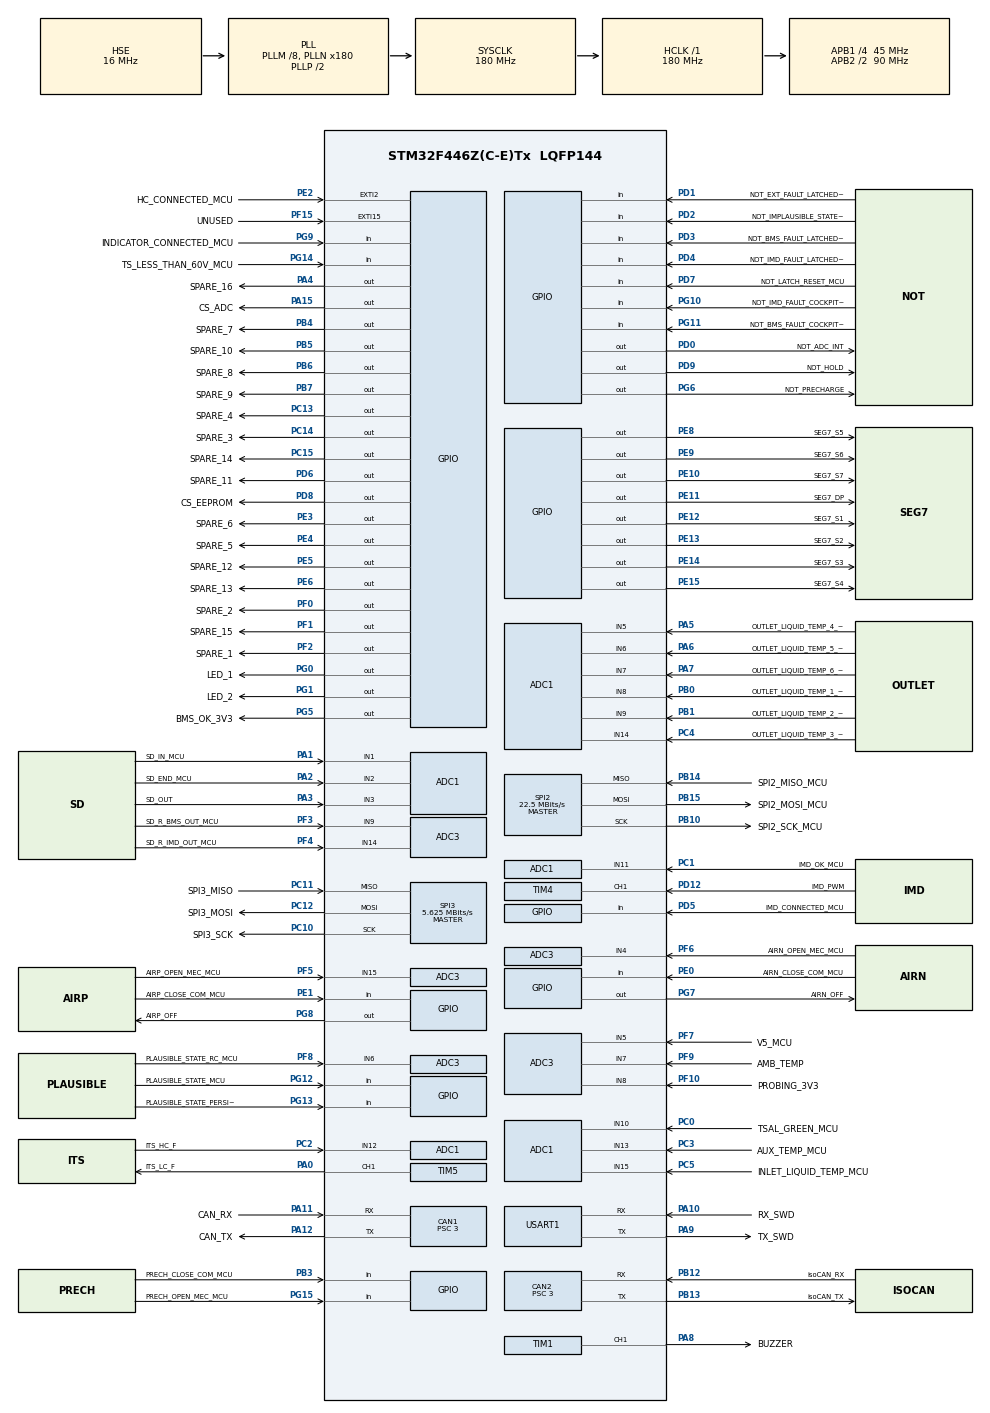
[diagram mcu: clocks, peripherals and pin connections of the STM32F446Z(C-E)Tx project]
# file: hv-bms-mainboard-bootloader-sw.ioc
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ADC1.Channel-0\#ChannelRegularConversion=ADC_CHANNEL_15
ADC1.Channel-1\#ChannelRegularConversion=ADC_CHANNEL_1
ADC1.Channel-10\#ChannelRegularConversion=ADC_CHANNEL_11
ADC1.Channel-11\#ChannelRegularConversion=ADC_CHANNEL_12
ADC1.Channel-12\#ChannelRegularConversion=ADC_CHANNEL_13
ADC1.Channel-13\#ChannelRegularConversion=ADC_CHANNEL_14
ADC1.Channel-14\#ChannelRegularConversion=ADC_CHANNEL_15
ADC1.Channel-2\#ChannelRegularConversion=ADC_CHANNEL_2
ADC1.Channel-3\#ChannelRegularConversion=ADC_CHANNEL_3
ADC1.Channel-4\#ChannelRegularConversion=ADC_CHANNEL_5
ADC1.Channel-5\#ChannelRegularConversion=ADC_CHANNEL_6
ADC1.Channel-6\#ChannelRegularConversion=ADC_CHANNEL_7
ADC1.Channel-7\#ChannelRegularConversion=ADC_CHANNEL_8
ADC1.Channel-8\#ChannelRegularConversion=ADC_CHANNEL_9
ADC1.Channel-9\#ChannelRegularConversion=ADC_CHANNEL_10
ADC1.ClockPrescaler=ADC_CLOCK_SYNC_PCLK_DIV4
ADC1.DiscontinuousConvMode=DISABLE
ADC1.EOCSelection=ADC_EOC_SEQ_CONV
ADC1.NbrOfConversion=15
ADC1.NbrOfConversionFlag=1
ADC1.Rank-0\#ChannelRegularConversion=1
ADC1.Rank-1\#ChannelRegularConversion=2
ADC1.Rank-10\#ChannelRegularConversion=11
ADC1.Rank-11\#ChannelRegularConversion=12
ADC1.Rank-12\#ChannelRegularConversion=13
ADC1.Rank-13\#ChannelRegularConversion=14
ADC1.Rank-14\#ChannelRegularConversion=15
ADC1.Rank-2\#ChannelRegularConversion=3
ADC1.Rank-3\#ChannelRegularConversion=4
ADC1.Rank-4\#ChannelRegularConversion=5
ADC1.Rank-5\#ChannelRegularConversion=6
ADC1.Rank-6\#ChannelRegularConversion=7
ADC1.Rank-7\#ChannelRegularConversion=8
ADC1.Rank-8\#ChannelRegularConversion=9
ADC1.Rank-9\#ChannelRegularConversion=10
ADC1.SamplingTime-0\#ChannelRegularConversion=ADC_SAMPLETIME_15CYCLES
ADC1.SamplingTime-1\#ChannelRegularConversion=ADC_SAMPLETIME_15CYCLES
ADC1.SamplingTime-10\#ChannelRegularConversion=ADC_SAMPLETIME_15CYCLES
ADC1.SamplingTime-11\#ChannelRegularConversion=ADC_SAMPLETIME_15CYCLES
ADC1.SamplingTime-12\#ChannelRegularConversion=ADC_SAMPLETIME_15CYCLES
ADC1.SamplingTime-13\#ChannelRegularConversion=ADC_SAMPLETIME_15CYCLES
ADC1.SamplingTime-14\#ChannelRegularConversion=ADC_SAMPLETIME_15CYCLES
ADC1.SamplingTime-2\#ChannelRegularConversion=ADC_SAMPLETIME_15CYCLES
ADC1.SamplingTime-3\#ChannelRegularConversion=ADC_SAMPLETIME_15CYCLES
ADC1.SamplingTime-4\#ChannelRegularConversion=ADC_SAMPLETIME_15CYCLES
ADC1.SamplingTime-5\#ChannelRegularConversion=ADC_SAMPLETIME_15CYCLES
ADC1.SamplingTime-6\#ChannelRegularConversion=ADC_SAMPLETIME_15CYCLES
ADC1.SamplingTime-7\#ChannelRegularConversion=ADC_SAMPLETIME_15CYCLES
ADC1.SamplingTime-8\#ChannelRegularConversion=ADC_SAMPLETIME_15CYCLES
ADC1.SamplingTime-9\#ChannelRegularConversion=ADC_SAMPLETIME_15CYCLES
ADC1.master=1
ADC3.Channel-10\#ChannelRegularConversion=ADC_CHANNEL_8
ADC3.Channel-11\#ChannelRegularConversion=ADC_CHANNEL_9
ADC3.Channel-12\#ChannelRegularConversion=ADC_CHANNEL_14
ADC3.Channel-13\#ChannelRegularConversion=ADC_CHANNEL_15
ADC3.Channel-6\#ChannelRegularConversion=ADC_CHANNEL_4
ADC3.Channel-7\#ChannelRegularConversion=ADC_CHANNEL_5
ADC3.Channel-8\#ChannelRegularConversion=ADC_CHANNEL_6
ADC3.Channel-9\#ChannelRegularConversion=ADC_CHANNEL_7
ADC3.EOCSelection=ADC_EOC_SEQ_CONV
ADC3.NbrOfConversion=8
ADC3.NbrOfConversionFlag=1
ADC3.Rank-10\#ChannelRegularConversion=5
ADC3.Rank-11\#ChannelRegularConversion=6
ADC3.Rank-12\#ChannelRegularConversion=7
ADC3.Rank-13\#ChannelRegularConversion=8
ADC3.Rank-6\#ChannelRegularConversion=1
ADC3.Rank-7\#ChannelRegularConversion=2
ADC3.Rank-8\#ChannelRegularConversion=3
ADC3.Rank-9\#ChannelRegularConversion=4
ADC3.SamplingTime-10\#ChannelRegularConversion=ADC_SAMPLETIME_15CYCLES
ADC3.SamplingTime-11\#ChannelRegularConversion=ADC_SAMPLETIME_15CYCLES
ADC3.SamplingTime-12\#ChannelRegularConversion=ADC_SAMPLETIME_15CYCLES
ADC3.SamplingTime-13\#ChannelRegularConversion=ADC_SAMPLETIME_3CYCLES
ADC3.SamplingTime-6\#ChannelRegularConversion=ADC_SAMPLETIME_15CYCLES
ADC3.SamplingTime-7\#ChannelRegularConversion=ADC_SAMPLETIME_15CYCLES
ADC3.SamplingTime-8\#ChannelRegularConversion=ADC_SAMPLETIME_15CYCLES
ADC3.SamplingTime-9\#ChannelRegularConversion=ADC_SAMPLETIME_15CYCLES
ADC3.ScanConvMode=ENABLE
CAN1.BS1=CAN_BS1_12TQ
CAN1.BS2=CAN_BS2_2TQ
CAN1.CalculateBaudRate=1000000
CAN1.CalculateTimeBit=1000
CAN1.CalculateTimeQuantum=66.66666666666666
CAN1.Prescaler=3
CAN2.BS1=CAN_BS1_12TQ
CAN2.BS2=CAN_BS2_2TQ
CAN2.CalculateBaudRate=1000000
CAN2.CalculateTimeBit=1000
CAN2.CalculateTimeQuantum=66.66666666666666
CAN2.Prescaler=3
Dma.ADC1.0.Direction=DMA_PERIPH_TO_MEMORY
Dma.ADC1.0.FIFOMode=DMA_FIFOMODE_DISABLE
Dma.ADC1.0.Instance=DMA2_Stream0
Dma.ADC1.0.MemDataAlignment=DMA_MDATAALIGN_HALFWORD
Dma.ADC1.0.MemInc=DMA_MINC_ENABLE
Dma.ADC1.0.Mode=DMA_CIRCULAR
Dma.ADC1.0.PeriphDataAlignment=DMA_PDATAALIGN_HALFWORD
Dma.ADC1.0.PeriphInc=DMA_PINC_DISABLE
Dma.ADC1.0.Priority=DMA_PRIORITY_LOW
Dma.ADC3.1.Direction=DMA_PERIPH_TO_MEMORY
Dma.ADC3.1.FIFOMode=DMA_FIFOMODE_DISABLE
Dma.ADC3.1.Instance=DMA2_Stream1
Dma.ADC3.1.MemDataAlignment=DMA_MDATAALIGN_HALFWORD
Dma.ADC3.1.MemInc=DMA_MINC_ENABLE
Dma.ADC3.1.Mode=DMA_CIRCULAR
Dma.ADC3.1.PeriphDataAlignment=DMA_PDATAALIGN_HALFWORD
Dma.ADC3.1.PeriphInc=DMA_PINC_DISABLE
Dma.ADC3.1.Priority=DMA_PRIORITY_LOW
Dma.Request0=ADC1
Dma.Request1=ADC3
Mcu.Family=STM32F4
Mcu.Name=STM32F446Z(C-E)Tx
Mcu.Package=LQFP144
NVIC.CAN1_RX0_IRQn=true\:0\:0\:false\:false\:true\:true\:true\:true
NVIC.CAN1_RX1_IRQn=true\:0\:0\:false\:false\:true\:true\:true\:true
NVIC.CAN2_RX0_IRQn=true\:0\:0\:false\:false\:true\:true\:true\:true
NVIC.CAN2_RX1_IRQn=true\:0\:0\:false\:false\:true\:true\:true\:true
NVIC.DMA2_Stream0_IRQn=true\:0\:0\:false\:false\:true\:false\:true\:true
NVIC.DMA2_Stream1_IRQn=true\:0\:0\:false\:false\:true\:false\:true\:true
NVIC.EXTI2_IRQn=true\:0\:0\:false\:false\:true\:true\:true\:true
NVIC.PriorityGroup=NVIC_PRIORITYGROUP_4
NVIC.TIM4_IRQn=true\:0\:0\:false\:false\:true\:true\:true\:true
NVIC.TIM6_DAC_IRQn=true\:0\:0\:false\:false\:true\:true\:true\:true
NVIC.TIM7_IRQn=true\:0\:0\:false\:false\:true\:true\:true\:true
PA0-WKUP.GPIO_Label=ITS_LC_F
PA0-WKUP.Signal=S_TIM5_CH1
PA1.GPIO_Label=SD_IN_MCU
PA1.Signal=ADCx_IN1
PA10.GPIO_Label=RX_SWD
PA10.Mode=Asynchronous
PA10.Signal=USART1_RX
PA11.GPIO_Label=CAN_RX
PA11.Mode=CAN_Activate
PA11.Signal=CAN1_RX
PA12.GPIO_Label=CAN_TX
PA12.Mode=CAN_Activate
PA12.Signal=CAN1_TX
PA13.GPIO_Label=SWDIO
PA13.Mode=Serial_Wire
PA13.Signal=SYS_JTMS-SWDIO
PA14.GPIO_Label=SWCLK
PA14.Mode=Serial_Wire
PA14.Signal=SYS_JTCK-SWCLK
PA15.GPIO_Label=CS_ADC
PA15.Signal=GPIO_Output
PA2.GPIO_Label=SD_END_MCU
PA2.Signal=ADCx_IN2
PA3.GPIO_Label=SD_OUT
PA3.Signal=ADCx_IN3
PA4.GPIO_Label=SPARE_16
PA4.Signal=GPIO_Output
PA5.GPIO_Label=OUTLET_LIQUID_TEMP_4_MCU
PA5.Signal=ADCx_IN5
PA6.GPIO_Label=OUTLET_LIQUID_TEMP_5_MCU
PA6.Signal=ADCx_IN6
PA7.GPIO_Label=OUTLET_LIQUID_TEMP_6_MCU
PA7.Signal=ADCx_IN7
PA8.GPIO_Label=BUZZER
PA8.Signal=S_TIM1_CH1
PA9.GPIO_Label=TX_SWD
PA9.Mode=Asynchronous
PA9.Signal=USART1_TX
PB0.GPIO_Label=OUTLET_LIQUID_TEMP_1_MCU
PB0.Signal=ADCx_IN8
PB1.GPIO_Label=OUTLET_LIQUID_TEMP_2_MCU
PB1.Signal=ADCx_IN9
PB10.GPIO_Label=SPI2_SCK_MCU
PB10.Mode=Full_Duplex_Master
PB10.Signal=SPI2_SCK
PB12.GPIO_Label=isoCAN_RX
PB12.Mode=CAN_Activate
PB12.Signal=CAN2_RX
PB13.GPIO_Label=isoCAN_TX
PB13.Mode=CAN_Activate
PB13.Signal=CAN2_TX
PB14.GPIO_Label=SPI2_MISO_MCU
PB14.Mode=Full_Duplex_Master
PB14.Signal=SPI2_MISO
PB15.GPIO_Label=SPI2_MOSI_MCU
PB15.Mode=Full_Duplex_Master
PB15.Signal=SPI2_MOSI
PB3.GPIO_Label=PRECH_CLOSE_COM_MCU
PB3.Signal=GPIO_Input
PB4.GPIO_Label=SPARE_7
PB4.Signal=GPIO_Output
PB5.GPIO_Label=SPARE_10
PB5.Signal=GPIO_Output
PB6.GPIO_Label=SPARE_8
PB6.Signal=GPIO_Output
PB7.GPIO_Label=SPARE_9
PB7.Signal=GPIO_Output
PC0.GPIO_Label=TSAL_GREEN_MCU
PC0.Signal=ADCx_IN10
PC1.GPIO_Label=IMD_OK_MCU
PC1.Signal=ADCx_IN11
PC10.GPIO_Label=SPI3_SCK
PC10.Mode=Full_Duplex_Master
PC10.Signal=SPI3_SCK
PC11.GPIO_Label=SPI3_MISO
PC11.Mode=Full_Duplex_Master
PC11.Signal=SPI3_MISO
PC12.GPIO_Label=SPI3_MOSI
PC12.Mode=Full_Duplex_Master
PC12.Signal=SPI3_MOSI
PC13.GPIO_Label=SPARE_4
PC13.Signal=GPIO_Output
PC14-OSC32_IN.GPIO_Label=SPARE_3
PC14-OSC32_IN.Signal=GPIO_Output
PC15-OSC32_OUT.GPIO_Label=SPARE_14
PC15-OSC32_OUT.Signal=GPIO_Output
PC2.GPIO_Label=ITS_HC_F
PC2.Signal=ADCx_IN12
PC3.GPIO_Label=AUX_TEMP_MCU
PC3.Signal=ADCx_IN13
PC4.GPIO_Label=OUTLET_LIQUID_TEMP_3_MCU
PC4.Signal=ADCx_IN14
PC5.GPIO_Label=INLET_LIQUID_TEMP_MCU
PC5.Signal=ADCx_IN15
PD0.GPIO_Label=NOT_ADC_INT
PD0.Signal=GPIO_Output
PD1.GPIO_Label=NOT_EXT_FAULT_LATCHED_MCU
PD1.Signal=GPIO_Input
PD12.GPIO_Label=IMD_PWM
PD12.Signal=S_TIM4_CH1
PD2.GPIO_Label=NOT_IMPLAUSIBLE_STATE_LATCHED_MCU
PD2.Signal=GPIO_Input
PD3.GPIO_Label=NOT_BMS_FAULT_LATCHED_MCU
PD3.Signal=GPIO_Input
PD4.GPIO_Label=NOT_IMD_FAULT_LATCHED_MCU
PD4.Signal=GPIO_Input
PD5.GPIO_Label=IMD_CONNECTED_MCU
PD5.Signal=GPIO_Input
PD6.GPIO_Label=SPARE_11
PD6.Signal=GPIO_Output
PD7.GPIO_Label=NOT_LATCH_RESET_MCU
PD7.Signal=GPIO_Input
PD8.GPIO_Label=CS_EEPROM
PD8.Signal=GPIO_Output
PD9.GPIO_Label=NOT_HOLD
PD9.Signal=GPIO_Output
PE0.GPIO_Label=AIRN_CLOSE_COM_MCU
PE0.GPIO_PuPd=GPIO_NOPULL
PE0.Signal=GPIO_Input
PE1.GPIO_Label=AIRP_CLOSE_COM_MCU
PE1.Signal=GPIO_Input
PE10.GPIO_Label=SEG7_S7
PE10.Signal=GPIO_Output
PE11.GPIO_Label=SEG7_DP
PE11.Signal=GPIO_Output
PE12.GPIO_Label=SEG7_S1
PE12.Signal=GPIO_Output
PE13.GPIO_Label=SEG7_S2
PE13.Signal=GPIO_Output
PE14.GPIO_Label=SEG7_S3
PE14.Signal=GPIO_Output
PE15.GPIO_Label=SEG7_S4
PE15.Signal=GPIO_Output
PE2.GPIO_Label=HC_CONNECTED_MCU
PE2.GPIO_ModeDefaultEXTI=GPIO_MODE_IT_RISING_FALLING
PE2.Signal=GPXTI2
PE3.GPIO_Label=SPARE_6
PE3.Signal=GPIO_Output
PE4.GPIO_Label=SPARE_5
PE4.Signal=GPIO_Output
PE5.GPIO_Label=SPARE_12
PE5.Signal=GPIO_Output
PE6.GPIO_Label=SPARE_13
PE6.Signal=GPIO_Output
PE8.GPIO_Label=SEG7_S5
PE8.Signal=GPIO_Output
PE9.GPIO_Label=SEG7_S6
PE9.Signal=GPIO_Output
PF0.GPIO_Label=SPARE_2
PF0.Signal=GPIO_Output
PF1.GPIO_Label=SPARE_15
PF1.Signal=GPIO_Output
PF10.GPIO_Label=PROBING_3V3
PF10.Mode=IN8
PF10.Signal=ADC3_IN8
PF15.GPIO_Label=UNUSED
PF15.GPIO_PuPd=GPIO_PULLDOWN
PF15.Signal=GPXTI15
PF2.GPIO_Label=SPARE_1
PF2.Signal=GPIO_Output
PF3.GPIO_Label=SD_R_BMS_OUT_MCU
PF3.Mode=IN9
PF3.Signal=ADC3_IN9
PF4.GPIO_Label=SD_R_IMD_OUT_MCU
PF4.Mode=IN14
PF4.Signal=ADC3_IN14
PF5.GPIO_Label=AIRP_OPEN_MEC_MCU
PF5.Mode=IN15
PF5.Signal=ADC3_IN15
PF6.GPIO_Label=AIRN_OPEN_MEC_MCU
PF6.Mode=IN4
PF6.Signal=ADC3_IN4
PF7.GPIO_Label=V5_MCU
PF7.Mode=IN5
PF7.Signal=ADC3_IN5
PF8.GPIO_Label=PLAUSIBLE_STATE_RC_MCU
PF8.Mode=IN6
PF8.Signal=ADC3_IN6
PF9.GPIO_Label=AMB_TEMP
PF9.Mode=IN7
PF9.Signal=ADC3_IN7
PG0.GPIO_Label=LED_1
PG0.Signal=GPIO_Output
PG1.GPIO_Label=LED_2
PG1.Signal=GPIO_Output
PG10.GPIO_Label=NOT_IMD_FAULT_COCKPIT_LED_MCU
PG10.Signal=GPIO_Input
PG11.GPIO_Label=NOT_BMS_FAULT_COCKPIT_LED_MCU
PG11.Signal=GPIO_Input
PG12.GPIO_Label=PLAUSIBLE_STATE_MCU
PG12.GPIO_PuPd=GPIO_NOPULL
PG12.Signal=GPIO_Input
PG13.GPIO_Label=PLAUSIBLE_STATE_PERSISTED_MCU
PG13.Signal=GPIO_Input
PG14.GPIO_Label=TS_LESS_THAN_60V_MCU
PG14.Signal=GPIO_Input
PG15.GPIO_Label=PRECH_OPEN_MEC_MCU
PG15.Signal=GPIO_Input
PG5.GPIO_Label=BMS_OK_3V3
PG5.Signal=GPIO_Output
PG6.GPIO_Label=NOT_PRECHARGE
PG6.Signal=GPIO_Output
PG7.GPIO_Label=AIRN_OFF
PG7.Signal=GPIO_Output
PG8.GPIO_Label=AIRP_OFF
PG8.Signal=GPIO_Output
PG9.GPIO_Label=INDICATOR_CONNECTED_MCU
PG9.Signal=GPIO_Input
PH0-OSC_IN.GPIO_Label=OSC_IN
PH0-OSC_IN.Mode=HSE-External-Oscillator
PH0-OSC_IN.Signal=RCC_OSC_IN
PH1-OSC_OUT.GPIO_Label=OSC_OUT
PH1-OSC_OUT.Mode=HSE-External-Oscillator
PH1-OSC_OUT.Signal=RCC_OSC_OUT
ProjectManager.HeapSize=0x200
ProjectManager.StackSize=0x400
ProjectManager.TargetToolchain=Makefile
RCC.AHBFreq_Value=180000000
RCC.APB1CLKDivider=RCC_HCLK_DIV4
RCC.APB1Freq_Value=45000000
RCC.APB1TimFreq_Value=90000000
RCC.APB2CLKDivider=RCC_HCLK_DIV2
RCC.APB2Freq_Value=90000000
RCC.APB2TimFreq_Value=180000000
RCC.CortexFreq_Value=180000000
RCC.HCLKFreq_Value=180000000
RCC.HSE_VALUE=16000000
RCC.PLLM=8
RCC.PLLN=180
RCC.PLLSourceVirtual=RCC_PLLSOURCE_HSE
RCC.SYSCLKFreq_VALUE=180000000
RCC.SYSCLKSource=RCC_SYSCLKSOURCE_PLLCLK
RCC.USBFreq_Value=180000000
RCC.VCOOutputFreq_Value=360000000
SH.ADCx_IN1.0=ADC1_IN1,IN1
SH.ADCx_IN10.0=ADC1_IN10,IN10
SH.ADCx_IN11.0=ADC1_IN11,IN11
SH.ADCx_IN12.0=ADC1_IN12,IN12
SH.ADCx_IN13.0=ADC1_IN13,IN13
SH.ADCx_IN14.0=ADC1_IN14,IN14
SH.ADCx_IN15.0=ADC1_IN15,IN15
SH.ADCx_IN2.0=ADC1_IN2,IN2
SH.ADCx_IN3.0=ADC1_IN3,IN3
SH.ADCx_IN5.0=ADC1_IN5,IN5
SH.ADCx_IN6.0=ADC1_IN6,IN6
SH.ADCx_IN7.0=ADC1_IN7,IN7
SH.ADCx_IN8.0=ADC1_IN8,IN8
SH.ADCx_IN9.0=ADC1_IN9,IN9
SH.S_TIM1_CH1.0=TIM1_CH1,PWM Generation1 CH1
SH.S_TIM4_CH1.0=TIM4_CH1,PWM_Input_1
SH.S_TIM5_CH1.0=TIM5_CH1,PWM Generation1 CH1
SPI2.BaudRatePrescaler=SPI_BAUDRATEPRESCALER_2
SPI2.CalculateBaudRate=22.5 MBits/s
SPI2.Direction=SPI_DIRECTION_2LINES
SPI2.Mode=SPI_MODE_MASTER
SPI2.VirtualType=VM_MASTER
SPI3.BaudRatePrescaler=SPI_BAUDRATEPRESCALER_8
SPI3.CLKPhase=SPI_PHASE_1EDGE
SPI3.CalculateBaudRate=5.625 MBits/s
SPI3.Direction=SPI_DIRECTION_2LINES
SPI3.Mode=SPI_MODE_MASTER
SPI3.VirtualType=VM_MASTER
TIM1.Channel-PWM\ Generation1\ CH1=TIM_CHANNEL_1
TIM4.Channel-PWM\ Generation1\ CH1=TIM_CHANNEL_1
TIM4.Prescaler=89
TIM5.AutoReloadPreload=TIM_AUTORELOAD_PRELOAD_ENABLE
TIM5.Channel-PWM\ Generation1\ CH1=TIM_CHANNEL_1
TIM5.Period=1000
TIM5.Prescaler=8999
TIM6.Period=999
TIM6.Prescaler=89
USART1.VirtualMode=VM_ASYNC
VP_ADC1_Vref_Input.Mode=IN-Vrefint
VP_TIM1_VS_ClockSourceINT.Mode=Internal
VP_TIM2_VS_ClockSourceINT.Mode=Internal
VP_TIM4_VS_ClockSourceINT.Mode=Internal
VP_TIM6_VS_ClockSourceINT.Mode=Enable_Timer
VP_TIM7_VS_ClockSourceINT.Mode=Enable_Timer
board=custom

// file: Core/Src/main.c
/* USER CODE BEGIN Header */
/**
  ******************************************************************************
  * @file           : main.c
  * @brief          : Main program body
  ******************************************************************************
  * @attention
  *
  * Copyright (c) 2026 STMicroelectronics.
  * All rights reserved.
  *
  * This software is licensed under terms that can be found in the LICENSE file
  * in the root directory of this software component.
  * If no LICENSE file comes with this software, it is provided AS-IS.
  *
  ******************************************************************************
  */
/* USER CODE END Header */
#include "main.h"

/* USER CODE BEGIN Includes */

#include "Core/Inc/main.h"
#include "boot.h"
#include "stm32f4xx_hal.h"
#include "stm32f4xx_hal_gpio.h"

/* USER CODE END Includes */

ADC_HandleTypeDef hadc1;
ADC_HandleTypeDef hadc3;
DMA_HandleTypeDef hdma_adc1;
DMA_HandleTypeDef hdma_adc3;

CAN_HandleTypeDef hcan1;
CAN_HandleTypeDef hcan2;

SPI_HandleTypeDef hspi2;
SPI_HandleTypeDef hspi3;

TIM_HandleTypeDef htim1;
TIM_HandleTypeDef htim2;
TIM_HandleTypeDef htim4;
TIM_HandleTypeDef htim5;
TIM_HandleTypeDef htim6;
TIM_HandleTypeDef htim7;

UART_HandleTypeDef huart1;

void SystemClock_Config(void);
static void MX_GPIO_Init(void);
static void MX_DMA_Init(void);
static void MX_ADC1_Init(void);
static void MX_CAN1_Init(void);
static void MX_CAN2_Init(void);
static void MX_ADC3_Init(void);
static void MX_SPI2_Init(void);
static void MX_TIM1_Init(void);
static void MX_TIM2_Init(void);
static void MX_TIM4_Init(void);
static void MX_USART1_UART_Init(void);
static void MX_SPI3_Init(void);
static void MX_TIM6_Init(void);
static void MX_TIM7_Init(void);
static void MX_TIM5_Init(void);

int main(void) {

    /* MCU Configuration--------------------------------------------------------*/

    /* Reset of all peripherals, Initializes the Flash interface and the Systick. */
    HAL_Init();

    /* Configure the system clock */
    SystemClock_Config();

    /* Initialize all configured peripherals */
    MX_GPIO_Init();
    MX_DMA_Init();
    MX_ADC1_Init();
    MX_CAN1_Init();
    MX_CAN2_Init();
    MX_ADC3_Init();
    MX_SPI2_Init();
    MX_TIM1_Init();
    MX_TIM2_Init();
    MX_TIM4_Init();
    MX_USART1_UART_Init();
    MX_SPI3_Init();
    MX_TIM6_Init();
    MX_TIM7_Init();
    MX_TIM5_Init();

    /* Infinite loop */
    /* USER CODE BEGIN WHILE */

    BootInit();

    uint32_t ticks = HAL_GetTick();
    constexpr uint32_t keepalive_interval = 400;
    while (1) {

        BootTask();

        if (HAL_GetTick() - ticks >= keepalive_interval) {
            HAL_GPIO_TogglePin(LED_1_GPIO_Port, LED_1_Pin);
            ticks = HAL_GetTick();
        }

        /* USER CODE END WHILE */

    }
}

void SystemClock_Config(void) {
    RCC_OscInitTypeDef RCC_OscInitStruct = { 0 };
    RCC_ClkInitTypeDef RCC_ClkInitStruct = { 0 };

    /** Configure the main internal regulator output voltage
  */
    __HAL_RCC_PWR_CLK_ENABLE();
    __HAL_PWR_VOLTAGESCALING_CONFIG(PWR_REGULATOR_VOLTAGE_SCALE1);

    /** Initializes the RCC Oscillators according to the specified parameters
  * in the RCC_OscInitTypeDef structure.
  */
    RCC_OscInitStruct.OscillatorType = RCC_OSCILLATORTYPE_HSE;
    RCC_OscInitStruct.HSEState = RCC_HSE_ON;
    RCC_OscInitStruct.PLL.PLLState = RCC_PLL_ON;
    RCC_OscInitStruct.PLL.PLLSource = RCC_PLLSOURCE_HSE;
    RCC_OscInitStruct.PLL.PLLM = 8;
    RCC_OscInitStruct.PLL.PLLN = 180;
    RCC_OscInitStruct.PLL.PLLP = RCC_PLLP_DIV2;
    RCC_OscInitStruct.PLL.PLLQ = 2;
    RCC_OscInitStruct.PLL.PLLR = 2;
    if (HAL_RCC_OscConfig(&RCC_OscInitStruct) != HAL_OK) {
        Error_Handler();
    }

    /** Activate the Over-Drive mode
  */
    if (HAL_PWREx_EnableOverDrive() != HAL_OK) {
        Error_Handler();
    }

    /** Initializes the CPU, AHB and APB buses clocks
  */
    RCC_ClkInitStruct.ClockType = RCC_CLOCKTYPE_HCLK | RCC_CLOCKTYPE_SYSCLK | RCC_CLOCKTYPE_PCLK1 | RCC_CLOCKTYPE_PCLK2;
    RCC_ClkInitStruct.SYSCLKSource = RCC_SYSCLKSOURCE_PLLCLK;
    RCC_ClkInitStruct.AHBCLKDivider = RCC_SYSCLK_DIV1;
    RCC_ClkInitStruct.APB1CLKDivider = RCC_HCLK_DIV4;
    RCC_ClkInitStruct.APB2CLKDivider = RCC_HCLK_DIV2;

    if (HAL_RCC_ClockConfig(&RCC_ClkInitStruct, FLASH_LATENCY_5) != HAL_OK) {
        Error_Handler();
    }
}

static void MX_ADC1_Init(void) {

    ADC_ChannelConfTypeDef sConfig = { 0 };

    /** Configure the global features of the ADC (Clock, Resolution, Data Alignment and number of conversion)
  */
    hadc1.Instance = ADC1;
    hadc1.Init.ClockPrescaler = ADC_CLOCK_SYNC_PCLK_DIV4;
    hadc1.Init.Resolution = ADC_RESOLUTION_12B;
    hadc1.Init.ScanConvMode = ENABLE;
    hadc1.Init.ContinuousConvMode = DISABLE;
    hadc1.Init.DiscontinuousConvMode = DISABLE;
    hadc1.Init.ExternalTrigConvEdge = ADC_EXTERNALTRIGCONVEDGE_NONE;
    hadc1.Init.ExternalTrigConv = ADC_SOFTWARE_START;
    hadc1.Init.DataAlign = ADC_DATAALIGN_RIGHT;
    hadc1.Init.NbrOfConversion = 15;
    hadc1.Init.DMAContinuousRequests = DISABLE;
    hadc1.Init.EOCSelection = ADC_EOC_SEQ_CONV;
    if (HAL_ADC_Init(&hadc1) != HAL_OK) {
        Error_Handler();
    }

    /** Configure for the selected ADC regular channel its corresponding rank in the sequencer and its sample time.
  */
    sConfig.Channel = ADC_CHANNEL_15;
    sConfig.Rank = 1;
    sConfig.SamplingTime = ADC_SAMPLETIME_15CYCLES;
    if (HAL_ADC_ConfigChannel(&hadc1, &sConfig) != HAL_OK) {
        Error_Handler();
    }

    /** Configure for the selected ADC regular channel its corresponding rank in the sequencer and its sample time.
  */
    sConfig.Channel = ADC_CHANNEL_1;
    sConfig.Rank = 2;
    if (HAL_ADC_ConfigChannel(&hadc1, &sConfig) != HAL_OK) {
        Error_Handler();
    }

    /** Configure for the selected ADC regular channel its corresponding rank in the sequencer and its sample time.
  */
    sConfig.Channel = ADC_CHANNEL_2;
    sConfig.Rank = 3;
    if (HAL_ADC_ConfigChannel(&hadc1, &sConfig) != HAL_OK) {
        Error_Handler();
    }

    /** Configure for the selected ADC regular channel its corresponding rank in the sequencer and its sample time.
  */
    sConfig.Channel = ADC_CHANNEL_3;
    sConfig.Rank = 4;
    if (HAL_ADC_ConfigChannel(&hadc1, &sConfig) != HAL_OK) {
        Error_Handler();
    }

    /** Configure for the selected ADC regular channel its corresponding rank in the sequencer and its sample time.
  */
    sConfig.Channel = ADC_CHANNEL_5;
    sConfig.Rank = 5;
    if (HAL_ADC_ConfigChannel(&hadc1, &sConfig) != HAL_OK) {
        Error_Handler();
    }

    /** Configure for the selected ADC regular channel its corresponding rank in the sequencer and its sample time.
  */
    sConfig.Channel = ADC_CHANNEL_6;
    sConfig.Rank = 6;
    if (HAL_ADC_ConfigChannel(&hadc1, &sConfig) != HAL_OK) {
        Error_Handler();
    }

    /** Configure for the selected ADC regular channel its corresponding rank in the sequencer and its sample time.
  */
    sConfig.Channel = ADC_CHANNEL_7;
    sConfig.Rank = 7;
    if (HAL_ADC_ConfigChannel(&hadc1, &sConfig) != HAL_OK) {
        Error_Handler();
    }

    /** Configure for the selected ADC regular channel its corresponding rank in the sequencer and its sample time.
  */
    sConfig.Channel = ADC_CHANNEL_8;
    sConfig.Rank = 8;
    if (HAL_ADC_ConfigChannel(&hadc1, &sConfig) != HAL_OK) {
        Error_Handler();
    }

    /** Configure for the selected ADC regular channel its corresponding rank in the sequencer and its sample time.
  */
    sConfig.Channel = ADC_CHANNEL_9;
    sConfig.Rank = 9;
    if (HAL_ADC_ConfigChannel(&hadc1, &sConfig) != HAL_OK) {
        Error_Handler();
    }

    /** Configure for the selected ADC regular channel its corresponding rank in the sequencer and its sample time.
  */
    sConfig.Channel = ADC_CHANNEL_10;
    sConfig.Rank = 10;
    if (HAL_ADC_ConfigChannel(&hadc1, &sConfig) != HAL_OK) {
        Error_Handler();
    }

    /** Configure for the selected ADC regular channel its corresponding rank in the sequencer and its sample time.
  */
    sConfig.Channel = ADC_CHANNEL_11;
    sConfig.Rank = 11;
    if (HAL_ADC_ConfigChannel(&hadc1, &sConfig) != HAL_OK) {
        Error_Handler();
    }

    /** Configure for the selected ADC regular channel its corresponding rank in the sequencer and its sample time.
  */
    sConfig.Channel = ADC_CHANNEL_12;
    sConfig.Rank = 12;
    if (HAL_ADC_ConfigChannel(&hadc1, &sConfig) != HAL_OK) {
        Error_Handler();
    }

    /** Configure for the selected ADC regular channel its corresponding rank in the sequencer and its sample time.
  */
    sConfig.Channel = ADC_CHANNEL_13;
    sConfig.Rank = 13;
    if (HAL_ADC_ConfigChannel(&hadc1, &sConfig) != HAL_OK) {
        Error_Handler();
    }

    /** Configure for the selected ADC regular channel its corresponding rank in the sequencer and its sample time.
  */
    sConfig.Channel = ADC_CHANNEL_14;
    sConfig.Rank = 14;
    if (HAL_ADC_ConfigChannel(&hadc1, &sConfig) != HAL_OK) {
        Error_Handler();
    }

    /** Configure for the selected ADC regular channel its corresponding rank in the sequencer and its sample time.
  */
    sConfig.Channel = ADC_CHANNEL_15;
    sConfig.Rank = 15;
    if (HAL_ADC_ConfigChannel(&hadc1, &sConfig) != HAL_OK) {
        Error_Handler();
    }
}

static void MX_ADC3_Init(void) {

    ADC_ChannelConfTypeDef sConfig = { 0 };

    /** Configure the global features of the ADC (Clock, Resolution, Data Alignment and number of conversion)
  */
    hadc3.Instance = ADC3;
    hadc3.Init.ClockPrescaler = ADC_CLOCK_SYNC_PCLK_DIV4;
    hadc3.Init.Resolution = ADC_RESOLUTION_12B;
    hadc3.Init.ScanConvMode = ENABLE;
    hadc3.Init.ContinuousConvMode = DISABLE;
    hadc3.Init.DiscontinuousConvMode = DISABLE;
    hadc3.Init.ExternalTrigConvEdge = ADC_EXTERNALTRIGCONVEDGE_NONE;
    hadc3.Init.ExternalTrigConv = ADC_SOFTWARE_START;
    hadc3.Init.DataAlign = ADC_DATAALIGN_RIGHT;
    hadc3.Init.NbrOfConversion = 8;
    hadc3.Init.DMAContinuousRequests = DISABLE;
    hadc3.Init.EOCSelection = ADC_EOC_SEQ_CONV;
    if (HAL_ADC_Init(&hadc3) != HAL_OK) {
        Error_Handler();
    }

    /** Configure for the selected ADC regular channel its corresponding rank in the sequencer and its sample time.
  */
    sConfig.Channel = ADC_CHANNEL_4;
    sConfig.Rank = 1;
    sConfig.SamplingTime = ADC_SAMPLETIME_15CYCLES;
    if (HAL_ADC_ConfigChannel(&hadc3, &sConfig) != HAL_OK) {
        Error_Handler();
    }

    /** Configure for the selected ADC regular channel its corresponding rank in the sequencer and its sample time.
  */
    sConfig.Channel = ADC_CHANNEL_5;
    sConfig.Rank = 2;
    if (HAL_ADC_ConfigChannel(&hadc3, &sConfig) != HAL_OK) {
        Error_Handler();
    }

    /** Configure for the selected ADC regular channel its corresponding rank in the sequencer and its sample time.
  */
    sConfig.Channel = ADC_CHANNEL_6;
    sConfig.Rank = 3;
    if (HAL_ADC_ConfigChannel(&hadc3, &sConfig) != HAL_OK) {
        Error_Handler();
    }

    /** Configure for the selected ADC regular channel its corresponding rank in the sequencer and its sample time.
  */
    sConfig.Channel = ADC_CHANNEL_7;
    sConfig.Rank = 4;
    if (HAL_ADC_ConfigChannel(&hadc3, &sConfig) != HAL_OK) {
        Error_Handler();
    }

    /** Configure for the selected ADC regular channel its corresponding rank in the sequencer and its sample time.
  */
    sConfig.Channel = ADC_CHANNEL_8;
    sConfig.Rank = 5;
    if (HAL_ADC_ConfigChannel(&hadc3, &sConfig) != HAL_OK) {
        Error_Handler();
    }

    /** Configure for the selected ADC regular channel its corresponding rank in the sequencer and its sample time.
  */
    sConfig.Channel = ADC_CHANNEL_9;
    sConfig.Rank = 6;
    if (HAL_ADC_ConfigChannel(&hadc3, &sConfig) != HAL_OK) {
        Error_Handler();
    }

    /** Configure for the selected ADC regular channel its corresponding rank in the sequencer and its sample time.
  */
    sConfig.Channel = ADC_CHANNEL_14;
    sConfig.Rank = 7;
    if (HAL_ADC_ConfigChannel(&hadc3, &sConfig) != HAL_OK) {
        Error_Handler();
    }

    /** Configure for the selected ADC regular channel its corresponding rank in the sequencer and its sample time.
  */
    sConfig.Channel = ADC_CHANNEL_15;
    sConfig.Rank = 8;
    sConfig.SamplingTime = ADC_SAMPLETIME_3CYCLES;
    if (HAL_ADC_ConfigChannel(&hadc3, &sConfig) != HAL_OK) {
        Error_Handler();
    }
}

static void MX_CAN1_Init(void) {

    hcan1.Instance = CAN1;
    hcan1.Init.Prescaler = 3;
    hcan1.Init.Mode = CAN_MODE_NORMAL;
    hcan1.Init.SyncJumpWidth = CAN_SJW_1TQ;
    hcan1.Init.TimeSeg1 = CAN_BS1_12TQ;
    hcan1.Init.TimeSeg2 = CAN_BS2_2TQ;
    hcan1.Init.TimeTriggeredMode = DISABLE;
    hcan1.Init.AutoBusOff = DISABLE;
    hcan1.Init.AutoWakeUp = DISABLE;
    hcan1.Init.AutoRetransmission = DISABLE;
    hcan1.Init.ReceiveFifoLocked = DISABLE;
    hcan1.Init.TransmitFifoPriority = DISABLE;
    if (HAL_CAN_Init(&hcan1) != HAL_OK) {
        Error_Handler();
    }
}

static void MX_CAN2_Init(void) {

    hcan2.Instance = CAN2;
    hcan2.Init.Prescaler = 3;
    hcan2.Init.Mode = CAN_MODE_NORMAL;
    hcan2.Init.SyncJumpWidth = CAN_SJW_1TQ;
    hcan2.Init.TimeSeg1 = CAN_BS1_12TQ;
    hcan2.Init.TimeSeg2 = CAN_BS2_2TQ;
    hcan2.Init.TimeTriggeredMode = DISABLE;
    hcan2.Init.AutoBusOff = DISABLE;
    hcan2.Init.AutoWakeUp = DISABLE;
    hcan2.Init.AutoRetransmission = DISABLE;
    hcan2.Init.ReceiveFifoLocked = DISABLE;
    hcan2.Init.TransmitFifoPriority = DISABLE;
    if (HAL_CAN_Init(&hcan2) != HAL_OK) {
        Error_Handler();
    }
}

static void MX_SPI2_Init(void) {

    /* SPI2 parameter configuration*/
    hspi2.Instance = SPI2;
    hspi2.Init.Mode = SPI_MODE_MASTER;
    hspi2.Init.Direction = SPI_DIRECTION_2LINES;
    hspi2.Init.DataSize = SPI_DATASIZE_8BIT;
    hspi2.Init.CLKPolarity = SPI_POLARITY_LOW;
    hspi2.Init.CLKPhase = SPI_PHASE_1EDGE;
    hspi2.Init.NSS = SPI_NSS_SOFT;
    hspi2.Init.BaudRatePrescaler = SPI_BAUDRATEPRESCALER_2;
    hspi2.Init.FirstBit = SPI_FIRSTBIT_MSB;
    hspi2.Init.TIMode = SPI_TIMODE_DISABLE;
    hspi2.Init.CRCCalculation = SPI_CRCCALCULATION_DISABLE;
    hspi2.Init.CRCPolynomial = 10;
    if (HAL_SPI_Init(&hspi2) != HAL_OK) {
        Error_Handler();
    }
}

static void MX_SPI3_Init(void) {

    /* SPI3 parameter configuration*/
    hspi3.Instance = SPI3;
    hspi3.Init.Mode = SPI_MODE_MASTER;
    hspi3.Init.Direction = SPI_DIRECTION_2LINES;
    hspi3.Init.DataSize = SPI_DATASIZE_8BIT;
    hspi3.Init.CLKPolarity = SPI_POLARITY_LOW;
    hspi3.Init.CLKPhase = SPI_PHASE_1EDGE;
    hspi3.Init.NSS = SPI_NSS_SOFT;
    hspi3.Init.BaudRatePrescaler = SPI_BAUDRATEPRESCALER_8;
    hspi3.Init.FirstBit = SPI_FIRSTBIT_MSB;
    hspi3.Init.TIMode = SPI_TIMODE_DISABLE;
    hspi3.Init.CRCCalculation = SPI_CRCCALCULATION_DISABLE;
    hspi3.Init.CRCPolynomial = 10;
    if (HAL_SPI_Init(&hspi3) != HAL_OK) {
        Error_Handler();
    }
}

static void MX_TIM1_Init(void) {

    TIM_ClockConfigTypeDef sClockSourceConfig = { 0 };
    TIM_MasterConfigTypeDef sMasterConfig = { 0 };
    TIM_OC_InitTypeDef sConfigOC = { 0 };
    TIM_BreakDeadTimeConfigTypeDef sBreakDeadTimeConfig = { 0 };

    htim1.Instance = TIM1;
    htim1.Init.Prescaler = 0;
    htim1.Init.CounterMode = TIM_COUNTERMODE_UP;
    htim1.Init.Period = 65535;
    htim1.Init.ClockDivision = TIM_CLOCKDIVISION_DIV1;
    htim1.Init.RepetitionCounter = 0;
    htim1.Init.AutoReloadPreload = TIM_AUTORELOAD_PRELOAD_DISABLE;
    if (HAL_TIM_Base_Init(&htim1) != HAL_OK) {
        Error_Handler();
    }
    sClockSourceConfig.ClockSource = TIM_CLOCKSOURCE_INTERNAL;
    if (HAL_TIM_ConfigClockSource(&htim1, &sClockSourceConfig) != HAL_OK) {
        Error_Handler();
    }
    if (HAL_TIM_PWM_Init(&htim1) != HAL_OK) {
        Error_Handler();
    }
    sMasterConfig.MasterOutputTrigger = TIM_TRGO_RESET;
    sMasterConfig.MasterSlaveMode = TIM_MASTERSLAVEMODE_DISABLE;
    if (HAL_TIMEx_MasterConfigSynchronization(&htim1, &sMasterConfig) != HAL_OK) {
        Error_Handler();
    }
    sConfigOC.OCMode = TIM_OCMODE_PWM1;
    sConfigOC.Pulse = 0;
    sConfigOC.OCPolarity = TIM_OCPOLARITY_HIGH;
    sConfigOC.OCNPolarity = TIM_OCNPOLARITY_HIGH;
    sConfigOC.OCFastMode = TIM_OCFAST_DISABLE;
    sConfigOC.OCIdleState = TIM_OCIDLESTATE_RESET;
    sConfigOC.OCNIdleState = TIM_OCNIDLESTATE_RESET;
    if (HAL_TIM_PWM_ConfigChannel(&htim1, &sConfigOC, TIM_CHANNEL_1) != HAL_OK) {
        Error_Handler();
    }
    sBreakDeadTimeConfig.OffStateRunMode = TIM_OSSR_DISABLE;
    sBreakDeadTimeConfig.OffStateIDLEMode = TIM_OSSI_DISABLE;
    sBreakDeadTimeConfig.LockLevel = TIM_LOCKLEVEL_OFF;
    sBreakDeadTimeConfig.DeadTime = 0;
    sBreakDeadTimeConfig.BreakState = TIM_BREAK_DISABLE;
    sBreakDeadTimeConfig.BreakPolarity = TIM_BREAKPOLARITY_HIGH;
    sBreakDeadTimeConfig.AutomaticOutput = TIM_AUTOMATICOUTPUT_DISABLE;
    if (HAL_TIMEx_ConfigBreakDeadTime(&htim1, &sBreakDeadTimeConfig) != HAL_OK) {
        Error_Handler();
    }
    HAL_TIM_MspPostInit(&htim1);
}

static void MX_TIM2_Init(void) {

    TIM_ClockConfigTypeDef sClockSourceConfig = { 0 };
    TIM_MasterConfigTypeDef sMasterConfig = { 0 };

    htim2.Instance = TIM2;
    htim2.Init.Prescaler = 0;
    htim2.Init.CounterMode = TIM_COUNTERMODE_UP;
    htim2.Init.Period = 4294967295;
    htim2.Init.ClockDivision = TIM_CLOCKDIVISION_DIV1;
    htim2.Init.AutoReloadPreload = TIM_AUTORELOAD_PRELOAD_DISABLE;
    if (HAL_TIM_Base_Init(&htim2) != HAL_OK) {
        Error_Handler();
    }
    sClockSourceConfig.ClockSource = TIM_CLOCKSOURCE_INTERNAL;
    if (HAL_TIM_ConfigClockSource(&htim2, &sClockSourceConfig) != HAL_OK) {
        Error_Handler();
    }
    sMasterConfig.MasterOutputTrigger = TIM_TRGO_RESET;
    sMasterConfig.MasterSlaveMode = TIM_MASTERSLAVEMODE_DISABLE;
    if (HAL_TIMEx_MasterConfigSynchronization(&htim2, &sMasterConfig) != HAL_OK) {
        Error_Handler();
    }
}

static void MX_TIM4_Init(void) {

    TIM_ClockConfigTypeDef sClockSourceConfig = { 0 };
    TIM_SlaveConfigTypeDef sSlaveConfig = { 0 };
    TIM_IC_InitTypeDef sConfigIC = { 0 };
    TIM_MasterConfigTypeDef sMasterConfig = { 0 };

    htim4.Instance = TIM4;
    htim4.Init.Prescaler = 89;
    htim4.Init.CounterMode = TIM_COUNTERMODE_UP;
    htim4.Init.Period = 65535;
    htim4.Init.ClockDivision = TIM_CLOCKDIVISION_DIV1;
    htim4.Init.AutoReloadPreload = TIM_AUTORELOAD_PRELOAD_DISABLE;
    if (HAL_TIM_Base_Init(&htim4) != HAL_OK) {
        Error_Handler();
    }
    sClockSourceConfig.ClockSource = TIM_CLOCKSOURCE_INTERNAL;
    if (HAL_TIM_ConfigClockSource(&htim4, &sClockSourceConfig) != HAL_OK) {
        Error_Handler();
    }
    if (HAL_TIM_IC_Init(&htim4) != HAL_OK) {
        Error_Handler();
    }
    sSlaveConfig.SlaveMode = TIM_SLAVEMODE_RESET;
    sSlaveConfig.InputTrigger = TIM_TS_TI1FP1;
    sSlaveConfig.TriggerPolarity = TIM_INPUTCHANNELPOLARITY_RISING;
    sSlaveConfig.TriggerPrescaler = TIM_ICPSC_DIV1;
    sSlaveConfig.TriggerFilter = 0;
    if (HAL_TIM_SlaveConfigSynchro(&htim4, &sSlaveConfig) != HAL_OK) {
        Error_Handler();
    }
    sConfigIC.ICPolarity = TIM_INPUTCHANNELPOLARITY_RISING;
    sConfigIC.ICSelection = TIM_ICSELECTION_DIRECTTI;
    sConfigIC.ICPrescaler = TIM_ICPSC_DIV1;
    sConfigIC.ICFilter = 0;
    if (HAL_TIM_IC_ConfigChannel(&htim4, &sConfigIC, TIM_CHANNEL_1) != HAL_OK) {
        Error_Handler();
    }
    sConfigIC.ICPolarity = TIM_INPUTCHANNELPOLARITY_FALLING;
    sConfigIC.ICSelection = TIM_ICSELECTION_INDIRECTTI;
    if (HAL_TIM_IC_ConfigChannel(&htim4, &sConfigIC, TIM_CHANNEL_2) != HAL_OK) {
        Error_Handler();
    }
    sMasterConfig.MasterOutputTrigger = TIM_TRGO_RESET;
    sMasterConfig.MasterSlaveMode = TIM_MASTERSLAVEMODE_DISABLE;
    if (HAL_TIMEx_MasterConfigSynchronization(&htim4, &sMasterConfig) != HAL_OK) {
        Error_Handler();
    }
}

static void MX_TIM5_Init(void) {

    TIM_MasterConfigTypeDef sMasterConfig = { 0 };
    TIM_OC_InitTypeDef sConfigOC = { 0 };

    htim5.Instance = TIM5;
    htim5.Init.Prescaler = 8999;
    htim5.Init.CounterMode = TIM_COUNTERMODE_UP;
    htim5.Init.Period = 1000;
    htim5.Init.ClockDivision = TIM_CLOCKDIVISION_DIV1;
    htim5.Init.AutoReloadPreload = TIM_AUTORELOAD_PRELOAD_ENABLE;
    if (HAL_TIM_PWM_Init(&htim5) != HAL_OK) {
        Error_Handler();
    }
    sMasterConfig.MasterOutputTrigger = TIM_TRGO_RESET;
    sMasterConfig.MasterSlaveMode = TIM_MASTERSLAVEMODE_DISABLE;
    if (HAL_TIMEx_MasterConfigSynchronization(&htim5, &sMasterConfig) != HAL_OK) {
        Error_Handler();
    }
    sConfigOC.OCMode = TIM_OCMODE_PWM1;
    sConfigOC.Pulse = 0;
    sConfigOC.OCPolarity = TIM_OCPOLARITY_HIGH;
    sConfigOC.OCFastMode = TIM_OCFAST_DISABLE;
    if (HAL_TIM_PWM_ConfigChannel(&htim5, &sConfigOC, TIM_CHANNEL_1) != HAL_OK) {
        Error_Handler();
    }
    HAL_TIM_MspPostInit(&htim5);
}

static void MX_TIM6_Init(void) {

    TIM_MasterConfigTypeDef sMasterConfig = { 0 };

    htim6.Instance = TIM6;
    htim6.Init.Prescaler = 89;
    htim6.Init.CounterMode = TIM_COUNTERMODE_UP;
    htim6.Init.Period = 999;
    htim6.Init.AutoReloadPreload = TIM_AUTORELOAD_PRELOAD_DISABLE;
    if (HAL_TIM_Base_Init(&htim6) != HAL_OK) {
        Error_Handler();
    }
    sMasterConfig.MasterOutputTrigger = TIM_TRGO_RESET;
    sMasterConfig.MasterSlaveMode = TIM_MASTERSLAVEMODE_DISABLE;
    if (HAL_TIMEx_MasterConfigSynchronization(&htim6, &sMasterConfig) != HAL_OK) {
        Error_Handler();
    }
}

static void MX_TIM7_Init(void) {

    TIM_MasterConfigTypeDef sMasterConfig = { 0 };

    htim7.Instance = TIM7;
    htim7.Init.Prescaler = 0;
    htim7.Init.CounterMode = TIM_COUNTERMODE_UP;
    htim7.Init.Period = 65535;
    htim7.Init.AutoReloadPreload = TIM_AUTORELOAD_PRELOAD_DISABLE;
    if (HAL_TIM_Base_Init(&htim7) != HAL_OK) {
        Error_Handler();
    }
    sMasterConfig.MasterOutputTrigger = TIM_TRGO_RESET;
    sMasterConfig.MasterSlaveMode = TIM_MASTERSLAVEMODE_DISABLE;
    if (HAL_TIMEx_MasterConfigSynchronization(&htim7, &sMasterConfig) != HAL_OK) {
        Error_Handler();
    }
}

static void MX_USART1_UART_Init(void) {

    huart1.Instance = USART1;
    huart1.Init.BaudRate = 115200;
    huart1.Init.WordLength = UART_WORDLENGTH_8B;
    huart1.Init.StopBits = UART_STOPBITS_1;
    huart1.Init.Parity = UART_PARITY_NONE;
    huart1.Init.Mode = UART_MODE_TX_RX;
    huart1.Init.HwFlowCtl = UART_HWCONTROL_NONE;
    huart1.Init.OverSampling = UART_OVERSAMPLING_16;
    if (HAL_UART_Init(&huart1) != HAL_OK) {
        Error_Handler();
    }
}

static void MX_DMA_Init(void) {

    /* DMA controller clock enable */
    __HAL_RCC_DMA2_CLK_ENABLE();

    /* DMA interrupt init */
    /* DMA2_Stream0_IRQn interrupt configuration */
    HAL_NVIC_SetPriority(DMA2_Stream0_IRQn, 0, 0);
    HAL_NVIC_EnableIRQ(DMA2_Stream0_IRQn);
    /* DMA2_Stream1_IRQn interrupt configuration */
    HAL_NVIC_SetPriority(DMA2_Stream1_IRQn, 0, 0);
    HAL_NVIC_EnableIRQ(DMA2_Stream1_IRQn);
}

static void MX_GPIO_Init(void) {
    GPIO_InitTypeDef GPIO_InitStruct = { 0 };

    /* GPIO Ports Clock Enable */
    __HAL_RCC_GPIOE_CLK_ENABLE();
    __HAL_RCC_GPIOC_CLK_ENABLE();
    __HAL_RCC_GPIOF_CLK_ENABLE();
    __HAL_RCC_GPIOH_CLK_ENABLE();
    __HAL_RCC_GPIOA_CLK_ENABLE();
    __HAL_RCC_GPIOB_CLK_ENABLE();
    __HAL_RCC_GPIOG_CLK_ENABLE();
    __HAL_RCC_GPIOD_CLK_ENABLE();

    /*Configure GPIO pin Output Level */
    HAL_GPIO_WritePin(GPIOE, SPARE_6_Pin | SPARE_5_Pin | SPARE_12_Pin | SPARE_13_Pin | SEG7_S5_Pin | SEG7_S6_Pin | SEG7_S7_Pin | SEG7_DP_Pin | SEG7_S1_Pin | SEG7_S2_Pin | SEG7_S3_Pin | SEG7_S4_Pin, GPIO_PIN_RESET);

    /*Configure GPIO pin Output Level */
    HAL_GPIO_WritePin(GPIOC, SPARE_4_Pin | SPARE_3_Pin | SPARE_14_Pin, GPIO_PIN_RESET);

    /*Configure GPIO pin Output Level */
    HAL_GPIO_WritePin(GPIOF, SPARE_2_Pin | SPARE_15_Pin | SPARE_1_Pin, GPIO_PIN_RESET);

    /*Configure GPIO pin Output Level */
    HAL_GPIO_WritePin(GPIOA, SPARE_16_Pin | CS_ADC_Pin, GPIO_PIN_RESET);

    /*Configure GPIO pin Output Level */
    HAL_GPIO_WritePin(GPIOG, LED_1_Pin | LED_2_Pin | BMS_OK_3V3_Pin | NOT_PRECHARGE_Pin | AIRN_OFF_Pin | AIRP_OFF_Pin, GPIO_PIN_RESET);

    /*Configure GPIO pin Output Level */
    HAL_GPIO_WritePin(GPIOD, CS_EEPROM_Pin | NOT_HOLD_Pin | NOT_ADC_INT_Pin | SPARE_11_Pin, GPIO_PIN_RESET);

    /*Configure GPIO pin Output Level */
    HAL_GPIO_WritePin(GPIOB, SPARE_7_Pin | SPARE_10_Pin | SPARE_8_Pin | SPARE_9_Pin, GPIO_PIN_RESET);

    /*Configure GPIO pin : HC_CONNECTED_MCU_Pin */
    GPIO_InitStruct.Pin = HC_CONNECTED_MCU_Pin;
    GPIO_InitStruct.Mode = GPIO_MODE_IT_RISING_FALLING;
    GPIO_InitStruct.Pull = GPIO_NOPULL;
    HAL_GPIO_Init(HC_CONNECTED_MCU_GPIO_Port, &GPIO_InitStruct);

    /*Configure GPIO pins : SPARE_6_Pin SPARE_5_Pin SPARE_12_Pin SPARE_13_Pin
                           SEG7_S5_Pin SEG7_S6_Pin SEG7_S7_Pin SEG7_DP_Pin
                           SEG7_S1_Pin SEG7_S2_Pin SEG7_S3_Pin SEG7_S4_Pin */
    GPIO_InitStruct.Pin = SPARE_6_Pin | SPARE_5_Pin | SPARE_12_Pin | SPARE_13_Pin | SEG7_S5_Pin | SEG7_S6_Pin | SEG7_S7_Pin | SEG7_DP_Pin | SEG7_S1_Pin | SEG7_S2_Pin | SEG7_S3_Pin | SEG7_S4_Pin;
    GPIO_InitStruct.Mode = GPIO_MODE_OUTPUT_PP;
    GPIO_InitStruct.Pull = GPIO_NOPULL;
    GPIO_InitStruct.Speed = GPIO_SPEED_FREQ_LOW;
    HAL_GPIO_Init(GPIOE, &GPIO_InitStruct);

    /*Configure GPIO pins : SPARE_4_Pin SPARE_3_Pin SPARE_14_Pin */
    GPIO_InitStruct.Pin = SPARE_4_Pin | SPARE_3_Pin | SPARE_14_Pin;
    GPIO_InitStruct.Mode = GPIO_MODE_OUTPUT_PP;
    GPIO_InitStruct.Pull = GPIO_NOPULL;
    GPIO_InitStruct.Speed = GPIO_SPEED_FREQ_LOW;
    HAL_GPIO_Init(GPIOC, &GPIO_InitStruct);

    /*Configure GPIO pins : SPARE_2_Pin SPARE_15_Pin SPARE_1_Pin */
    GPIO_InitStruct.Pin = SPARE_2_Pin | SPARE_15_Pin | SPARE_1_Pin;
    GPIO_InitStruct.Mode = GPIO_MODE_OUTPUT_PP;
    GPIO_InitStruct.Pull = GPIO_NOPULL;
    GPIO_InitStruct.Speed = GPIO_SPEED_FREQ_LOW;
    HAL_GPIO_Init(GPIOF, &GPIO_InitStruct);

    /*Configure GPIO pins : SPARE_16_Pin CS_ADC_Pin */
    GPIO_InitStruct.Pin = SPARE_16_Pin | CS_ADC_Pin;
    GPIO_InitStruct.Mode = GPIO_MODE_OUTPUT_PP;
    GPIO_InitStruct.Pull = GPIO_NOPULL;
    GPIO_InitStruct.Speed = GPIO_SPEED_FREQ_LOW;
    HAL_GPIO_Init(GPIOA, &GPIO_InitStruct);

    /*Configure GPIO pin : UNUSED_Pin */
    GPIO_InitStruct.Pin = UNUSED_Pin;
    GPIO_InitStruct.Mode = GPIO_MODE_IT_RISING;
    GPIO_InitStruct.Pull = GPIO_PULLDOWN;
    HAL_GPIO_Init(UNUSED_GPIO_Port, &GPIO_InitStruct);

    /*Configure GPIO pins : LED_1_Pin LED_2_Pin BMS_OK_3V3_Pin NOT_PRECHARGE_Pin
                           AIRN_OFF_Pin AIRP_OFF_Pin */
    GPIO_InitStruct.Pin = LED_1_Pin | LED_2_Pin | BMS_OK_3V3_Pin | NOT_PRECHARGE_Pin | AIRN_OFF_Pin | AIRP_OFF_Pin;
    GPIO_InitStruct.Mode = GPIO_MODE_OUTPUT_PP;
    GPIO_InitStruct.Pull = GPIO_NOPULL;
    GPIO_InitStruct.Speed = GPIO_SPEED_FREQ_LOW;
    HAL_GPIO_Init(GPIOG, &GPIO_InitStruct);

    /*Configure GPIO pins : CS_EEPROM_Pin NOT_HOLD_Pin NOT_ADC_INT_Pin SPARE_11_Pin */
    GPIO_InitStruct.Pin = CS_EEPROM_Pin | NOT_HOLD_Pin | NOT_ADC_INT_Pin | SPARE_11_Pin;
    GPIO_InitStruct.Mode = GPIO_MODE_OUTPUT_PP;
    GPIO_InitStruct.Pull = GPIO_NOPULL;
    GPIO_InitStruct.Speed = GPIO_SPEED_FREQ_LOW;
    HAL_GPIO_Init(GPIOD, &GPIO_InitStruct);

    /*Configure GPIO pins : NOT_EXT_FAULT_LATCHED_MCU_Pin NOT_IMPLAUSIBLE_STATE_LATCHED_MCU_Pin NOT_BMS_FAULT_LATCHED_MCU_Pin NOT_IMD_FAULT_LATCHED_MCU_Pin
                           IMD_CONNECTED_MCU_Pin NOT_LATCH_RESET_MCU_Pin */
    GPIO_InitStruct.Pin = NOT_EXT_FAULT_LATCHED_MCU_Pin | NOT_IMPLAUSIBLE_STATE_LATCHED_MCU_Pin | NOT_BMS_FAULT_LATCHED_MCU_Pin | NOT_IMD_FAULT_LATCHED_MCU_Pin | IMD_CONNECTED_MCU_Pin | NOT_LATCH_RESET_MCU_Pin;
    GPIO_InitStruct.Mode = GPIO_MODE_INPUT;
    GPIO_InitStruct.Pull = GPIO_NOPULL;
    HAL_GPIO_Init(GPIOD, &GPIO_InitStruct);

    /*Configure GPIO pins : INDICATOR_CONNECTED_MCU_Pin NOT_IMD_FAULT_COCKPIT_LED_MCU_Pin NOT_BMS_FAULT_COCKPIT_LED_MCU_Pin PLAUSIBLE_STATE_MCU_Pin
                           PLAUSIBLE_STATE_PERSISTED_MCU_Pin TS_LESS_THAN_60V_MCU_Pin PRECH_OPEN_MEC_MCU_Pin */
    GPIO_InitStruct.Pin = INDICATOR_CONNECTED_MCU_Pin | NOT_IMD_FAULT_COCKPIT_LED_MCU_Pin | NOT_BMS_FAULT_COCKPIT_LED_MCU_Pin | PLAUSIBLE_STATE_MCU_Pin | PLAUSIBLE_STATE_PERSISTED_MCU_Pin | TS_LESS_THAN_60V_MCU_Pin | PRECH_OPEN_MEC_MCU_Pin;
    GPIO_InitStruct.Mode = GPIO_MODE_INPUT;
    GPIO_InitStruct.Pull = GPIO_NOPULL;
    HAL_GPIO_Init(GPIOG, &GPIO_InitStruct);

    /*Configure GPIO pin : PRECH_CLOSE_COM_MCU_Pin */
    GPIO_InitStruct.Pin = PRECH_CLOSE_COM_MCU_Pin;
    GPIO_InitStruct.Mode = GPIO_MODE_INPUT;
    GPIO_InitStruct.Pull = GPIO_NOPULL;
    HAL_GPIO_Init(PRECH_CLOSE_COM_MCU_GPIO_Port, &GPIO_InitStruct);

    /*Configure GPIO pins : SPARE_7_Pin SPARE_10_Pin SPARE_8_Pin SPARE_9_Pin */
    GPIO_InitStruct.Pin = SPARE_7_Pin | SPARE_10_Pin | SPARE_8_Pin | SPARE_9_Pin;
    GPIO_InitStruct.Mode = GPIO_MODE_OUTPUT_PP;
    GPIO_InitStruct.Pull = GPIO_NOPULL;
    GPIO_InitStruct.Speed = GPIO_SPEED_FREQ_LOW;
    HAL_GPIO_Init(GPIOB, &GPIO_InitStruct);

    /*Configure GPIO pins : AIRN_CLOSE_COM_MCU_Pin AIRP_CLOSE_COM_MCU_Pin */
    GPIO_InitStruct.Pin = AIRN_CLOSE_COM_MCU_Pin | AIRP_CLOSE_COM_MCU_Pin;
    GPIO_InitStruct.Mode = GPIO_MODE_INPUT;
    GPIO_InitStruct.Pull = GPIO_NOPULL;
    HAL_GPIO_Init(GPIOE, &GPIO_InitStruct);

    /* EXTI interrupt init*/
    HAL_NVIC_SetPriority(EXTI2_IRQn, 0, 0);
    HAL_NVIC_EnableIRQ(EXTI2_IRQn);

}

void Error_Handler(void) {
    __disable_irq();
    while (1) {
    }
}
